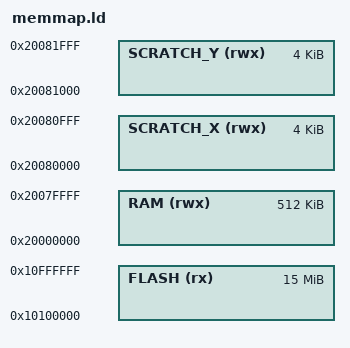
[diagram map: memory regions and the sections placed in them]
MEMORY
{
    FLASH(rx) : ORIGIN = 0x10100000, LENGTH = 15360k
    RAM(rwx)  : ORIGIN = 0x20000000, LENGTH = 512k
    SCRATCH_X(rwx) : ORIGIN = 0x20080000, LENGTH = 4k
    SCRATCH_Y(rwx) : ORIGIN = 0x20081000, LENGTH = 4k
}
